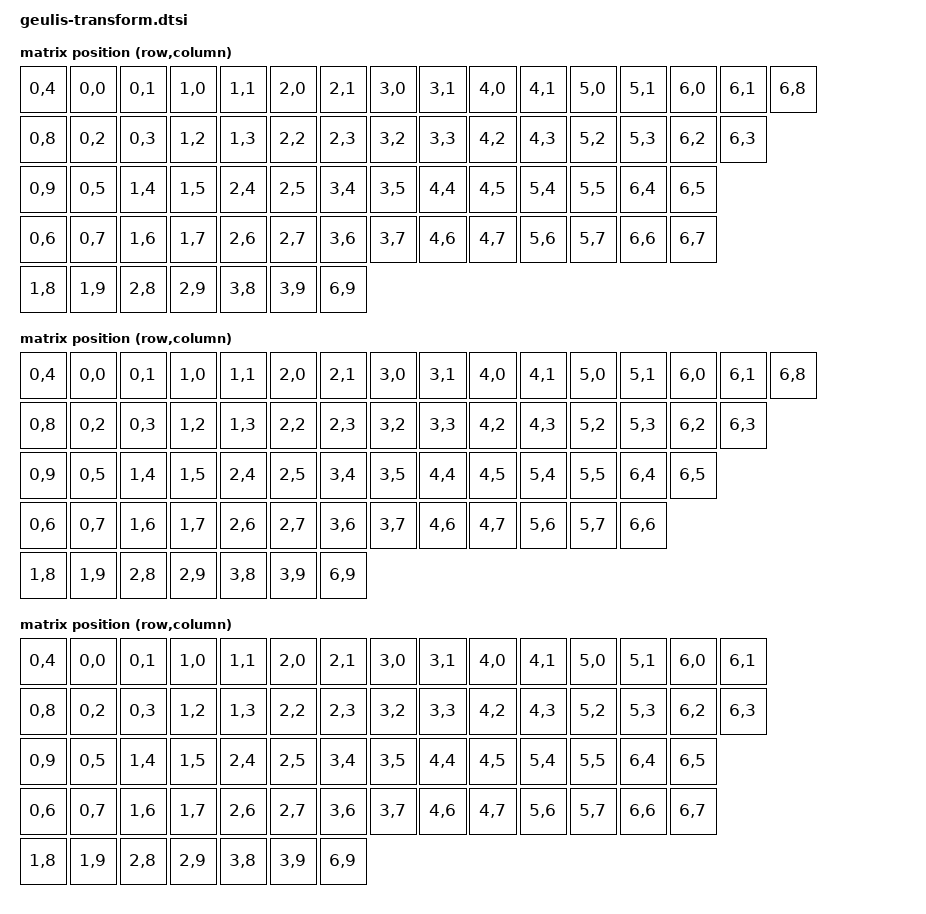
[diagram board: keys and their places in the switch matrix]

#include <dt-bindings/zmk/matrix_transform.h>

/ {
    // Split backspace and split right shift
    transform0: transform0 {
        compatible = "zmk,matrix-transform";
        columns = <10>;
        rows = <7>;

        map = <
			RC(0,4) RC(0,0) RC(0,1) RC(1,0) RC(1,1) RC(2,0) RC(2,1) RC(3,0) RC(3,1) RC(4,0) RC(4,1) RC(5,0) RC(5,1) RC(6,0) RC(6,1) RC(6,8)
			RC(0,8) RC(0,2) RC(0,3) RC(1,2) RC(1,3) RC(2,2) RC(2,3) RC(3,2) RC(3,3) RC(4,2) RC(4,3) RC(5,2) RC(5,3) RC(6,2) RC(6,3)
			RC(0,9) RC(0,5) RC(1,4) RC(1,5) RC(2,4) RC(2,5) RC(3,4) RC(3,5) RC(4,4) RC(4,5) RC(5,4) RC(5,5) RC(6,4) RC(6,5)
			RC(0,6) RC(0,7) RC(1,6) RC(1,7) RC(2,6) RC(2,7) RC(3,6) RC(3,7) RC(4,6) RC(4,7) RC(5,6) RC(5,7) RC(6,6) RC(6,7)
			RC(1,8) RC(1,9) RC(2,8) RC(2,9) RC(3,8) RC(3,9) RC(6,9)
        >;
    };

    // Split backspace and one right shift
    transform1: transform1 {
        compatible = "zmk,matrix-transform";
        columns = <10>;
        rows = <7>;

        map = <
			RC(0,4) RC(0,0) RC(0,1) RC(1,0) RC(1,1) RC(2,0) RC(2,1) RC(3,0) RC(3,1) RC(4,0) RC(4,1) RC(5,0) RC(5,1) RC(6,0) RC(6,1) RC(6,8)
			RC(0,8) RC(0,2) RC(0,3) RC(1,2) RC(1,3) RC(2,2) RC(2,3) RC(3,2) RC(3,3) RC(4,2) RC(4,3) RC(5,2) RC(5,3) RC(6,2) RC(6,3)
			RC(0,9) RC(0,5) RC(1,4) RC(1,5) RC(2,4) RC(2,5) RC(3,4) RC(3,5) RC(4,4) RC(4,5) RC(5,4) RC(5,5) RC(6,4) RC(6,5)
			RC(0,6) RC(0,7) RC(1,6) RC(1,7) RC(2,6) RC(2,7) RC(3,6) RC(3,7) RC(4,6) RC(4,7) RC(5,6) RC(5,7) RC(6,6)
			RC(1,8) RC(1,9) RC(2,8) RC(2,9) RC(3,8) RC(3,9) RC(6,9)
        >;
    };

    // One backspace and split right shift
    transform2: transform2 {
        compatible = "zmk,matrix-transform";
        columns = <10>;
        rows = <7>;

        map = <
			RC(0,4) RC(0,0) RC(0,1) RC(1,0) RC(1,1) RC(2,0) RC(2,1) RC(3,0) RC(3,1) RC(4,0) RC(4,1) RC(5,0) RC(5,1) RC(6,0) RC(6,1)
			RC(0,8) RC(0,2) RC(0,3) RC(1,2) RC(1,3) RC(2,2) RC(2,3) RC(3,2) RC(3,3) RC(4,2) RC(4,3) RC(5,2) RC(5,3) RC(6,2) RC(6,3)
			RC(0,9) RC(0,5) RC(1,4) RC(1,5) RC(2,4) RC(2,5) RC(3,4) RC(3,5) RC(4,4) RC(4,5) RC(5,4) RC(5,5) RC(6,4) RC(6,5)
			RC(0,6) RC(0,7) RC(1,6) RC(1,7) RC(2,6) RC(2,7) RC(3,6) RC(3,7) RC(4,6) RC(4,7) RC(5,6) RC(5,7) RC(6,6) RC(6,7)
			RC(1,8) RC(1,9) RC(2,8) RC(2,9) RC(3,8) RC(3,9) RC(6,9)
        >;
    };

    // One backspace and one right shift
    transform3: transform3 {
        compatible = "zmk,matrix-transform";
        columns = <10>;
        rows = <7>;

        map = <
			RC(0,4) RC(0,0) RC(0,1) RC(1,0) RC(1,1) RC(2,0) RC(2,1) RC(3,0) RC(3,1) RC(4,0) RC(4,1) RC(5,0) RC(5,1) RC(6,0) RC(6,1)
			RC(0,8) RC(0,2) RC(0,3) RC(1,2) RC(1,3) RC(2,2) RC(2,3) RC(3,2) RC(3,3) RC(4,2) RC(4,3) RC(5,2) RC(5,3) RC(6,2) RC(6,3)
			RC(0,9) RC(0,5) RC(1,4) RC(1,5) RC(2,4) RC(2,5) RC(3,4) RC(3,5) RC(4,4) RC(4,5) RC(5,4) RC(5,5) RC(6,4) RC(6,5)
			RC(0,6) RC(0,7) RC(1,6) RC(1,7) RC(2,6) RC(2,7) RC(3,6) RC(3,7) RC(4,6) RC(4,7) RC(5,6) RC(5,7) RC(6,6)
			RC(1,8) RC(1,9) RC(2,8) RC(2,9) RC(3,8) RC(3,9) RC(6,9)
        >;
    };
};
